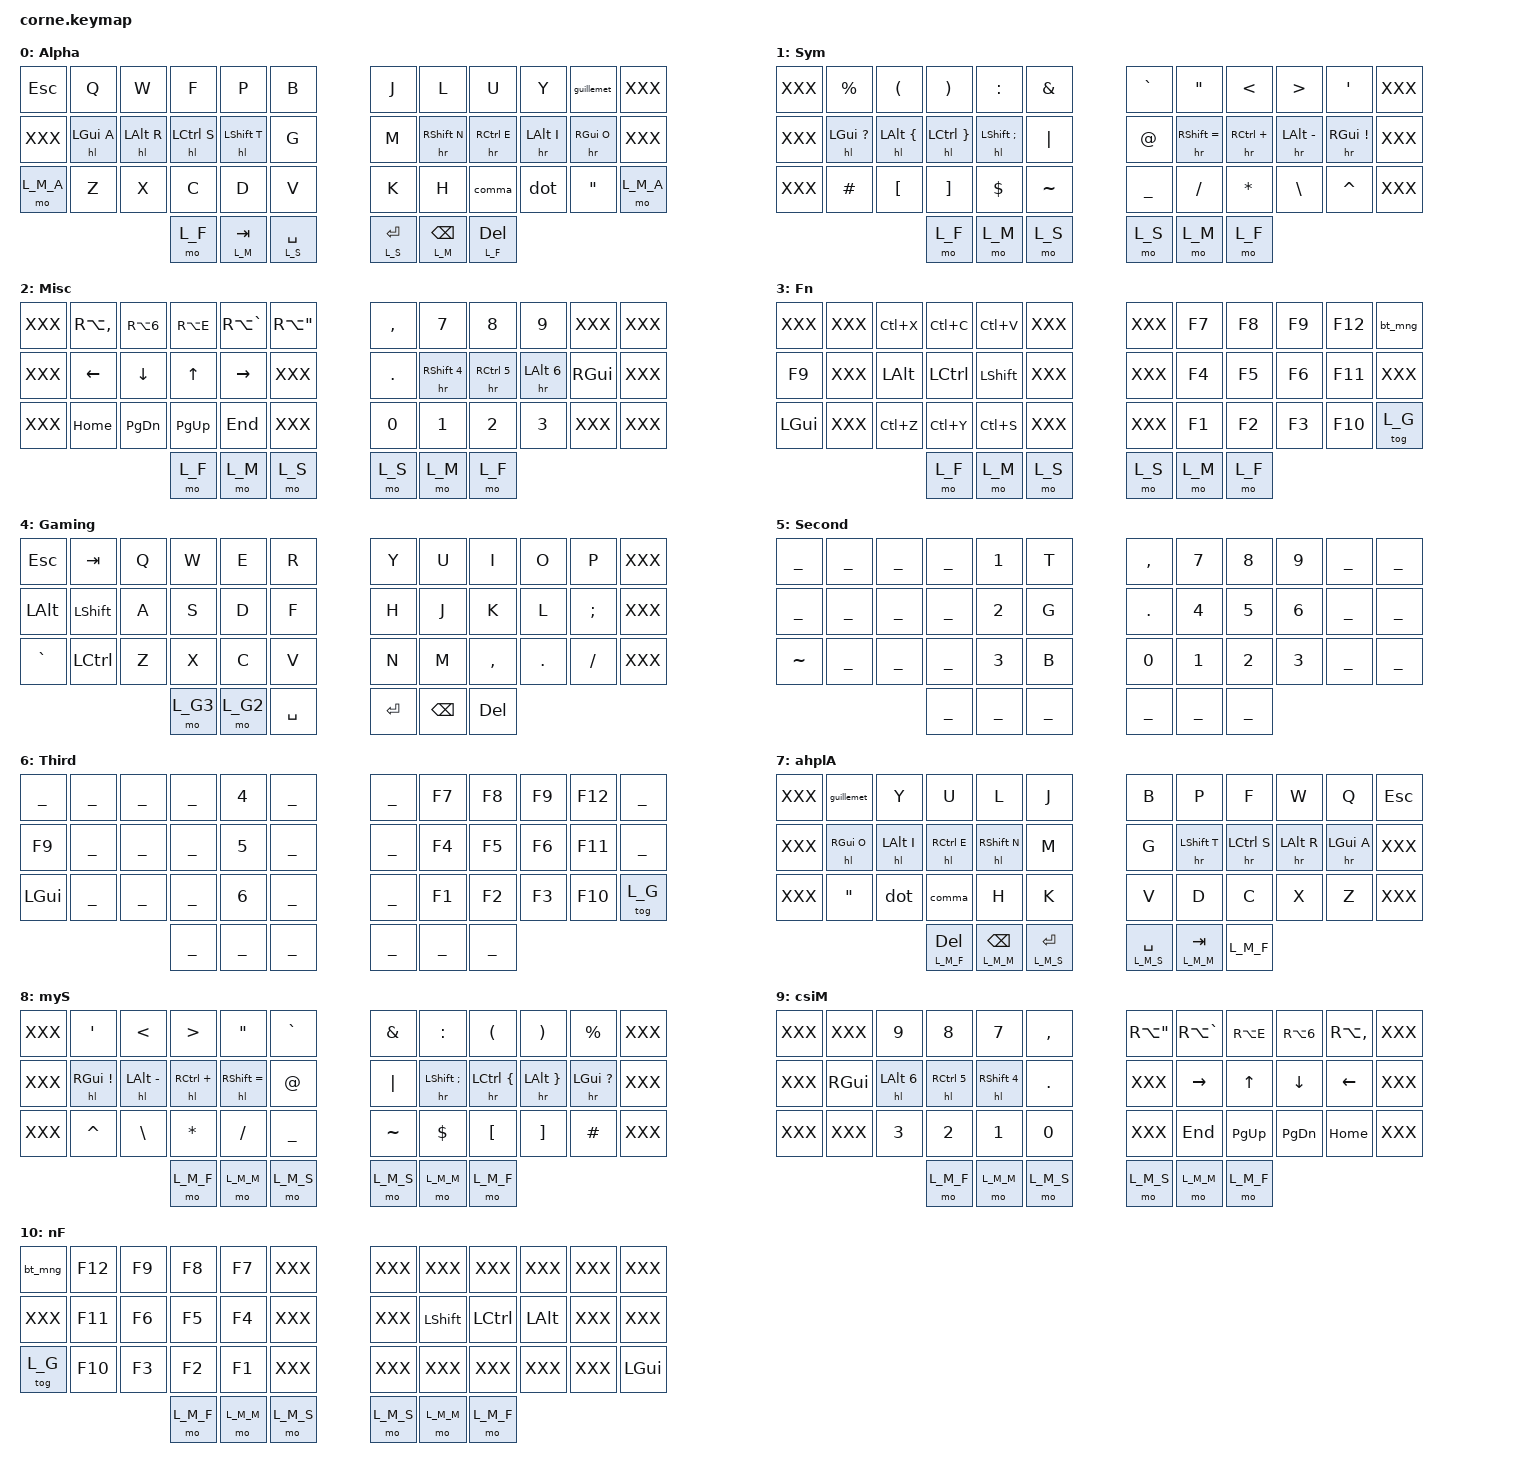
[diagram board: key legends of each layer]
#include <behaviors.dtsi>
#include <dt-bindings/zmk/keys.h>
#include <dt-bindings/zmk/bt.h>
#include <dt-bindings/zmk/ext_power.h>
#include "zmk-helpers/helper.h"
#include "./helpers.h"
#include "./keys.h"

/* Layers */

#define L_A 0 // Alpha
#define L_S 1 // Symbols
#define L_M 2 // Miscellaneous
#define L_F 3 // Functions
#define L_G 4 // Gaming
#define L_G2 5 // Gaming 2
#define L_G3 6 // Gaming 3
#define L_M_A 7 // Mirrored Alpha
#define L_M_S 8 // Mirrored Symbols
#define L_M_M 9 // Mirrored Miscellaneous
#define L_M_F 10 // Mirrored Functions

/* Home Row Mods */

// Left-hand side home row mod. The prefix `hl` somewhat stands for "home row mod on the left side".
MAKE_HRM(hl, &kp, &kp, RIGHT_SIDE_KEYS THUMB_KEYS)

// Right-hand side home row mod. The prefix `hr` somewhat stands for "home row mod on the right side".
MAKE_HRM(hr, &kp, &kp, LEFT_SIDE_KEYS THUMB_KEYS)

/* Misc */

ZMK_COMBO(caps_word, \
    &caps_word, \
    LM0 RM0, \
    L_A, \
    COMBO_TERM, \
    HRM_TAPPING_TERM \
)

ZMK_MOD_MORPH(bt_mng, \
    mods = <(MOD_LSFT|MOD_RSFT)>; \
    bindings = \
        <&bt BT_NXT>, \
        <&bt BT_CLR>; \
)

ZMK_MOD_MORPH(guillemet, \
    mods = <(MOD_LSFT|MOD_RSFT)>; \
    bindings = \
        <&kp RA(LBKT)>, \
        <&kp RA(RBKT)>; \
)

ZMK_MOD_MORPH(comma, \
    mods = <(MOD_LSFT|MOD_RSFT)>; \
    bindings = \
        <&kp COMMA>, \
        <&kp SQT>; \
)

ZMK_MOD_MORPH(dot, \
    mods = <(MOD_LSFT|MOD_RSFT)>; \
    bindings = \
        <&kp DOT>, \
        <&kp DOT>; \
)

// Enable double tap hold on layer keys to repeat the tap behavior.
&lt {
    quick-tap-ms = <250>;
};

/* Layers */

ZMK_LAYER(Alpha,
//╭────────────────┬────────────────┬────────────────┬────────────────┬────────────────┬────────────────╮        ╭────────────────┬────────────────┬────────────────┬────────────────┬─ « ────────────┬────────────────╮
    &kp ESC          &kp Q            &kp W            &kp F            &kp P            &kp B                     &kp J            &kp L            &kp U            &kp Y            &guillemet       XXX
//├────────────────┼────────────────┼────────────────┼────────────────┼────────────────┼────────────────┤        ├────────────────┼────────────────┼────────────────┼────────────────┼────────────────┼────────────────┤
    XXX              &hl LGUI A       &hl LALT R       &hl LCTRL S      &hl LSHFT T      &kp G                     &kp M            &hr RSHFT N      &hr RCTRL E      &hr LALT I       &hr RGUI O       XXX
//├────────────────┼────────────────┼────────────────┼────────────────┼────────────────┼────────────────┤        ├────────────────┼────────────────┼─ , ────────────┼─ . ────────────┼─ " ────────────┼────────────────┤
    &mo L_M_A        &kp Z            &kp X            &kp C            &kp D            &kp V                     &kp K            &kp H            &comma           &dot             &kp DQT          &mo L_M_A
//╰────────────────┴────────────────┴────────────────┼────────────────┼────────────────┼────────────────┤        ├────────────────┼────────────────┼────────────────┼────────────────┴────────────────┴────────────────╯
                                                       &mo L_F          &lt L_M TAB      &lt L_S SPACE             &lt L_S ENTER    &lt L_M BSPC     &lt L_F DEL
//                                                   ╰────────────────┴────────────────┴────────────────╯        ╰────────────────┴────────────────┴────────────────╯
)

ZMK_LAYER(Sym,
//╭────────────────┬─ % ────────────┬─ ( ────────────┬─ ) ────────────┬─ : ────────────┬─ & ────────────╮        ╭─ ` ────────────┬─ " ────────────┬─ < ────────────┬─ > ────────────┬─ ' ────────────┬────────────────╮
    XXX              &kp PERCENT      &kp LPAR         &kp RPAR         &kp COLON        &kp AMPERSAND             &kp GRAVE        &kp DQT          &kp LT           &kp GT           &kp SQT          XXX
//├────────────────┼─ ? ────────────┼─ { ────────────┼─ } ────────────┼─ ; ────────────┼─ | ────────────┤        ├─ @ ────────────┼─ = ────────────┼─ + ────────────┼─ - ────────────┼─ ! ────────────┼────────────────┤
    XXX              &hl LGUI QMARK   &hl LALT LBRC    &hl LCTRL RBRC   &hl LSHFT SEMI   &kp PIPE                  &kp AT           &hr RSHFT EQUAL  &hr RCTRL PLUS   &hr LALT MINUS   &hr RGUI EXCL    XXX
//├────────────────┼─ # ────────────┼─ [ ────────────┼─ ] ────────────┼─ $ ────────────┼─ ~ ────────────┤        ├─ _ ────────────┼─ / ────────────┼─ * ────────────┼─ \ ────────────┼─ ^ ────────────┼────────────────┤
    XXX              &kp HASH         &kp LBKT         &kp RBKT         &kp DOLLAR       &kp TILDE                 &kp UNDERSCORE   &kp SLASH        &kp ASTERISK     &kp BACKSLASH    &kp CARET        XXX
//╰────────────────┴────────────────┴────────────────┼────────────────┼────────────────┼────────────────┤        ├────────────────┼────────────────┼────────────────┼────────────────┴────────────────┴────────────────╯
                                                       &mo L_F          &mo L_M          &mo L_S                   &mo L_S          &mo L_M          &mo L_F
//                                                   ╰────────────────┴────────────────┴────────────────╯        ╰────────────────┴────────────────┴────────────────╯
)

ZMK_LAYER(Misc,
//╭────────────────┬─ ç ────────────┬─ ^ ────────────┬─ é ────────────┬─ ` ────────────┬─ ¨ ────────────╮        ╭────────────────┬────────────────┬────────────────┬────────────────┬────────────────┬────────────────╮
    XXX              &kp RA(COMMA)    &kp RA(N6)       &kp RA(E)        &kp RA(GRAVE)    &kp RA(DQT)               &kp COMMA        &kp N7           &kp N8           &kp N9           XXX              XXX
//├────────────────┼────────────────┼────────────────┼────────────────┼────────────────┼────────────────┤        ├────────────────┼────────────────┼────────────────┼────────────────┼────────────────┼────────────────┤
    XXX              &kp LEFT         &kp DOWN         &kp UP           &kp RIGHT        XXX                       &kp DOT          &hr RSHFT N4     &hr RCTRL N5     &hr LALT N6      &kp RGUI         XXX
//├────────────────┼────────────────┼────────────────┼────────────────┼────────────────┼────────────────┤        ├────────────────┼────────────────┼────────────────┼────────────────┼────────────────┼────────────────┤
    XXX              &kp HOME         &kp PG_DN        &kp PG_UP        &kp END          XXX                       &kp N0           &kp N1           &kp N2           &kp N3           XXX              XXX
//╰────────────────┴────────────────┴────────────────┼────────────────┼────────────────┼────────────────┤        ├────────────────┼────────────────┼────────────────┼────────────────┴────────────────┴────────────────╯
                                                       &mo L_F          &mo L_M          &mo L_S                   &mo L_S          &mo L_M          &mo L_F
//                                                   ╰────────────────┴────────────────┴────────────────╯        ╰────────────────┴────────────────┴────────────────╯
)

ZMK_LAYER(Fn,
//╭────────────────┬────────────────┬─ Cut ──────────┬─ Copy ─────────┬─ Paste ────────┬────────────────╮        ╭────────────────┬────────────────┬────────────────┬────────────────┬────────────────┬────────────────╮
    XXX              XXX              &kp LC(X)        &kp LC(C)        &kp LC(V)        XXX                       XXX              &kp F7           &kp F8           &kp F9           &kp F12          &bt_mng
//├────────────────┼────────────────┼────────────────┼────────────────┼────────────────┼────────────────┤        ├────────────────┼────────────────┼────────────────┼────────────────┼────────────────┼────────────────┤
    &kp F9           XXX              &kp LALT         &kp LCTRL        &kp LSHFT        XXX                       XXX              &kp F4           &kp F5           &kp F6           &kp F11          XXX
//├────────────────┼────────────────┼─ Undo  ────────┼─ Redo ─────────┼─ Save ─────────┼────────────────┤        ├────────────────┼────────────────┼────────────────┼────────────────┼────────────────┼────────────────┤
    &kp LGUI         XXX              &kp LC(Z)        &kp LC(Y)        &kp LC(S)        XXX                       XXX              &kp F1           &kp F2           &kp F3           &kp F10          &tog L_G
//╰────────────────┴────────────────┴────────────────┼────────────────┼────────────────┼────────────────┤        ├────────────────┼────────────────┼────────────────┼────────────────┴────────────────┴────────────────╯
                                                       &mo L_F          &mo L_M          &mo L_S                   &mo L_S          &mo L_M          &mo L_F
//                                                   ╰────────────────┴────────────────┴────────────────╯        ╰────────────────┴────────────────┴────────────────╯
)

ZMK_LAYER(Gaming,
//╭─────────────┬─────────────┬─────────────┬─────────────┬─────────────┬─────────────╮        ╭─────────────┬─────────────┬─────────────┬─────────────┬─────────────┬─────────────╮
    &kp ESC       &kp TAB       &kp Q         &kp W         &kp E         &kp R                  &kp Y         &kp U         &kp I         &kp O         &kp P         XXX
//├─────────────┼─────────────┼─────────────┼─────────────┼─────────────┼─────────────┤        ├─────────────┼─────────────┼─────────────┼─────────────┼─────────────┼─────────────┤
    &kp LALT      &kp LSHFT     &kp A         &kp S         &kp D         &kp F                  &kp H         &kp J         &kp K         &kp L         &kp SEMI      XXX
//├─ ` ─────────┼─────────────┼─────────────┼─────────────┼─────────────┼─────────────┤        ├─────────────┼─────────────┼─────────────┼─────────────┼─ / ─────────┼─────────────┤
    &kp GRAVE     &kp LCTRL     &kp Z         &kp X         &kp C         &kp V                  &kp N         &kp M         &kp COMMA     &kp DOT       &kp FSLH      XXX
//╰─────────────┴─────────────┴─────────────┼─────────────┼─────────────┼─────────────┤        ├─────────────┼─────────────┼─────────────┼─────────────┴─────────────┴─────────────╯
                                              &mo L_G3      &mo L_G2      &kp SPACE              &kp ENTER     &kp BSPC      &kp DEL
//                                          ╰─────────────┴─────────────┴─────────────╯        ╰─────────────┴─────────────┴─────────────╯
)

ZMK_LAYER(Second,
//╭─────────────┬─────────────┬─────────────┬─────────────┬─────────────┬─────────────╮        ╭─────────────┬─────────────┬─────────────┬─────────────┬─────────────┬─────────────╮
    ___           ___           ___           ___           &kp N1        &kp T                  &kp COMMA     &kp N7        &kp N8        &kp N9        ___           ___
//├─────────────┼─────────────┼─────────────┼─────────────┼─────────────┼─────────────┤        ├─────────────┼─────────────┼─────────────┼─────────────┼─────────────┼─────────────┤
    ___           ___           ___           ___           &kp N2        &kp G                  &kp DOT       &kp N4        &kp N5        &kp N6        ___           ___
//├─ ~ ─────────┼─────────────┼─────────────┼─────────────┼─────────────┼─────────────┤        ├─────────────┼─────────────┼─────────────┼─────────────┼─────────────┼─────────────┤
    &kp TILDE     ___           ___           ___           &kp N3        &kp B                  &kp N0        &kp N1        &kp N2        &kp N3        ___           ___
//╰─────────────┴─────────────┴─────────────┼─────────────┼─────────────┼─────────────┤        ├─────────────┼─────────────┼─────────────┼─────────────┴─────────────┴─────────────╯
                                              ___           ___           ___                    ___           ___           ___
//                                          ╰─────────────┴─────────────┴─────────────╯        ╰─────────────┴─────────────┴─────────────╯
)

ZMK_LAYER(Third,
//╭─────────────┬─────────────┬─────────────┬─────────────┬─────────────┬─────────────╮        ╭─────────────┬─────────────┬─────────────┬─────────────┬─────────────┬─────────────╮
    ___           ___           ___           ___           &kp N4        ___                    ___           &kp F7        &kp F8        &kp F9        &kp F12       ___
//├─────────────┼─────────────┼─────────────┼─────────────┼─────────────┼─────────────┤        ├─────────────┼─────────────┼─────────────┼─────────────┼─────────────┼─────────────┤
    &kp F9        ___           ___           ___           &kp N5        ___                    ___           &kp F4        &kp F5        &kp F6        &kp F11       ___
//├─────────────┼─────────────┼─────────────┼─────────────┼─────────────┼─────────────┤        ├─────────────┼─────────────┼─────────────┼─────────────┼─────────────┼─────────────┤
    &kp LGUI      ___           ___           ___           &kp N6        ___                    ___           &kp F1        &kp F2        &kp F3        &kp F10       &tog L_G
//╰─────────────┴─────────────┴─────────────┼─────────────┼─────────────┼─────────────┤        ├─────────────┼─────────────┼─────────────┼─────────────┴─────────────┴─────────────╯
                                              ___           ___           ___                    ___           ___           ___
//                                          ╰─────────────┴─────────────┴─────────────╯        ╰─────────────┴─────────────┴─────────────╯
)

ZMK_LAYER(ahplA,
//╭────────────────┬─ « ────────────┬────────────────┬────────────────┬────────────────┬────────────────╮        ╭────────────────┬────────────────┬────────────────┬────────────────┬────────────────┬────────────────╮
    XXX              &guillemet       &kp Y            &kp U            &kp L            &kp J                     &kp B            &kp P            &kp F            &kp W            &kp Q            &kp ESC
//├────────────────┼────────────────┼────────────────┼────────────────┼────────────────┼────────────────┤        ├────────────────┼────────────────┼────────────────┼────────────────┼────────────────┼────────────────┤
    XXX              &hl RGUI O       &hl LALT I       &hl RCTRL E      &hl RSHFT N      &kp M                     &kp G            &hr LSHFT T      &hr LCTRL S      &hr LALT R       &hr LGUI A       XXX
//├────────────────┼─ " ────────────┼─ . ────────────┼─ , ────────────┼────────────────┼────────────────┤        ├────────────────┼────────────────┼────────────────┼────────────────┼────────────────┼────────────────┤
    XXX              &kp DQT          &dot             &comma           &kp H            &kp K                     &kp V            &kp D            &kp C            &kp X            &kp Z            XXX
//╰────────────────┴────────────────┴────────────────┼────────────────┼────────────────┼────────────────┤        ├────────────────┼────────────────┼────────────────┼────────────────┴────────────────┴────────────────╯
                                                       &lt L_M_F DEL    &lt L_M_M BSPC   &lt L_M_S ENTER           &lt L_M_S SPACE  &lt L_M_M TAB    &kp L_M_F
//                                                   ╰────────────────┴────────────────┴────────────────╯        ╰────────────────┴────────────────┴────────────────╯
)

ZMK_LAYER(myS,
//╭────────────────┬─ ' ────────────┬─ < ────────────┬─ > ────────────┬─ " ────────────┬─ ` ────────────╮        ╭────────────────┬────────────────┬────────────────┬────────────────┬────────────────┬────────────────╮
    XXX              &kp SQT          &kp LT           &kp GT           &kp DQT          &kp GRAVE                 &kp AMPERSAND    &kp COLON        &kp LPAR         &kp RPAR         &kp PERCENT      XXX
//├────────────────┼─ ! ────────────┼─ - ────────────┼─ + ────────────┼─ = ────────────┼─ @ ────────────┤        ├────────────────┬────────────────┬────────────────┬────────────────┬────────────────┬────────────────┤
    XXX              &hl RGUI EXCL    &hl LALT MINUS   &hl RCTRL PLUS   &hl RSHFT EQUAL  &kp AT                    &kp PIPE         &hr LSHFT SEMI   &hr LCTRL LBRC   &hr LALT RBRC    &hr LGUI QMARK   XXX
//├────────────────┼─ ^ ────────────┼─ \ ────────────┼─ * ────────────┼─ / ────────────┼─ _ ────────────┤        ├────────────────┼────────────────┼────────────────┼────────────────┼────────────────┼────────────────┤
    XXX              &kp CARET        &kp BACKSLASH    &kp ASTERISK     &kp SLASH        &kp UNDERSCORE            &kp TILDE        &kp DOLLAR       &kp LBKT         &kp RBKT         &kp HASH         XXX
//╰────────────────┴────────────────┴────────────────┼────────────────┼────────────────┼────────────────┤        ├────────────────┼────────────────┼────────────────┼────────────────┴────────────────┴────────────────╯
                                                       &mo L_M_F        &mo L_M_M        &mo L_M_S                 &mo L_M_S        &mo L_M_M        &mo L_M_F
//                                                   ╰────────────────┴────────────────┴────────────────╯        ╰────────────────┴────────────────┴────────────────╯
)

ZMK_LAYER(csiM,
//╭────────────────┬────────────────┬────────────────┬────────────────┬────────────────┬────────────────╮        ╭────────────────┬────────────────┬────────────────┬────────────────┬────────────────┬────────────────╮
    XXX              XXX              &kp N9           &kp N8           &kp N7           &kp COMMA                 &kp RA(DQT)      &kp RA(GRAVE)    &kp RA(E)        &kp RA(N6)       &kp RA(COMMA)    XXX
//├────────────────┼────────────────┼────────────────┼────────────────┼────────────────┼────────────────┤        ├────────────────┬────────────────┬────────────────┬────────────────┬────────────────┬────────────────┤
    XXX              &kp RGUI         &hl LALT N6      &hl RCTRL N5     &hl RSHFT N4     &kp DOT                   XXX              &kp RIGHT        &kp UP           &kp DOWN         &kp LEFT         XXX
//├────────────────┼────────────────┼────────────────┼────────────────┼────────────────┼────────────────┤        ├────────────────┼────────────────┼────────────────┼────────────────┼────────────────┼────────────────┤
    XXX              XXX              &kp N3           &kp N2           &kp N1           &kp N0                    XXX              &kp END          &kp PG_UP        &kp PG_DN        &kp HOME         XXX
//╰────────────────┴────────────────┴────────────────┼────────────────┼────────────────┼────────────────┤        ├────────────────┼────────────────┼────────────────┼────────────────┴────────────────┴────────────────╯
                                                       &mo L_M_F        &mo L_M_M        &mo L_M_S                 &mo L_M_S        &mo L_M_M        &mo L_M_F
//                                                   ╰────────────────┴────────────────┴────────────────╯        ╰────────────────┴────────────────┴────────────────╯
)

ZMK_LAYER(nF,
//╭────────────────┬────────────────┬────────────────┬────────────────┬────────────────┬────────────────╮        ╭────────────────┬────────────────┬────────────────┬────────────────┬────────────────┬────────────────╮
    &bt_mng          &kp F12          &kp F9           &kp F8           &kp F7           XXX                       XXX              XXX              XXX              XXX              XXX              XXX
//├────────────────┼────────────────┼────────────────┼────────────────┼────────────────┼────────────────┤        ├────────────────┬────────────────┬────────────────┬────────────────┬────────────────┬────────────────┤
    XXX              &kp F11          &kp F6           &kp F5           &kp F4           XXX                       XXX              &kp LSHFT        &kp LCTRL        &kp LALT         XXX              XXX
//├────────────────┼────────────────┼────────────────┼────────────────┼────────────────┼────────────────┤        ├────────────────┼────────────────┼────────────────┼────────────────┼────────────────┼────────────────┤
    &tog L_G         &kp F10          &kp F3           &kp F2           &kp F1           XXX                       XXX              XXX              XXX              XXX              XXX              &kp LGUI
//╰────────────────┴────────────────┴────────────────┼────────────────┼────────────────┼────────────────┤        ├────────────────┼────────────────┼────────────────┼────────────────┴────────────────┴────────────────╯
                                                       &mo L_M_F        &mo L_M_M        &mo L_M_S                 &mo L_M_S        &mo L_M_M        &mo L_M_F
//                                                   ╰────────────────┴────────────────┴────────────────╯        ╰────────────────┴────────────────┴────────────────╯
)
